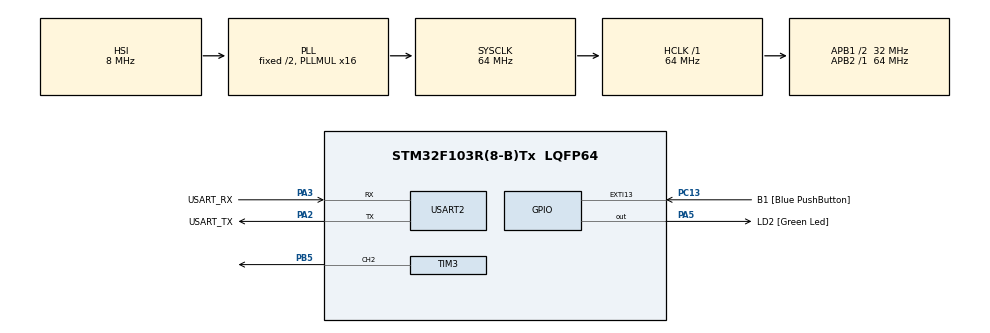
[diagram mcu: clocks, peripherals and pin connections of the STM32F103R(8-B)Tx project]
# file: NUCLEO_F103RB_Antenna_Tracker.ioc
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FREERTOS.Tasks01=blink01,24,128,StartBlink01,Default,NULL,Dynamic,NULL,NULL;PWM01,32,128,StartPWM01,Default,NULL,Dynamic,NULL,NULL
FREERTOS.configUSE_NEWLIB_REENTRANT=1
Mcu.Family=STM32F1
Mcu.Name=STM32F103R(8-B)Tx
Mcu.Package=LQFP64
NVIC.EXTI15_10_IRQn=true\:5\:0\:false\:false\:true\:true\:true\:true\:true
NVIC.PriorityGroup=NVIC_PRIORITYGROUP_4
NVIC.TIM4_IRQn=true\:15\:0\:false\:false\:true\:false\:false\:true\:true
NVIC.TimeBase=TIM4_IRQn
NVIC.TimeBaseIP=TIM4
PA13.GPIO_Label=TMS
PA13.Mode=Serial_Wire
PA13.Signal=SYS_JTMS-SWDIO
PA14.GPIO_Label=TCK
PA14.Mode=Serial_Wire
PA14.Signal=SYS_JTCK-SWCLK
PA2.GPIO_Label=USART_TX
PA2.GPIO_Mode=GPIO_MODE_AF_PP
PA2.GPIO_PuPd=GPIO_NOPULL
PA2.GPIO_Speed=GPIO_SPEED_FREQ_LOW
PA2.Mode=Asynchronous
PA2.Signal=USART2_TX
PA3.GPIO_Label=USART_RX
PA3.GPIO_Mode=GPIO_MODE_AF_PP
PA3.GPIO_PuPd=GPIO_NOPULL
PA3.GPIO_Speed=GPIO_SPEED_FREQ_LOW
PA3.Mode=Asynchronous
PA3.Signal=USART2_RX
PA5.GPIO_Label=LD2 [Green Led]
PA5.GPIO_ModeDefaultOutputPP=GPIO_MODE_OUTPUT_PP
PA5.GPIO_PuPd=GPIO_NOPULL
PA5.GPIO_Speed=GPIO_SPEED_FREQ_LOW
PA5.Signal=GPIO_Output
PB3.GPIO_Label=SWO
PB3.Signal=SYS_JTDO-TRACESWO
PB5.Signal=S_TIM3_CH2
PC13-TAMPER-RTC.GPIO_Label=B1 [Blue PushButton]
PC13-TAMPER-RTC.GPIO_PuPd=GPIO_NOPULL
PC13-TAMPER-RTC.Signal=GPXTI13
PC14-OSC32_IN.Mode=LSE-External-Oscillator
PC14-OSC32_IN.Signal=RCC_OSC32_IN
PC15-OSC32_OUT.Mode=LSE-External-Oscillator
PC15-OSC32_OUT.Signal=RCC_OSC32_OUT
PD0-OSC_IN.Mode=HSE-External-Clock-Source
PD0-OSC_IN.Signal=RCC_OSC_IN
PD1-OSC_OUT.Mode=HSE-External-Clock-Source
PD1-OSC_OUT.Signal=RCC_OSC_OUT
ProjectManager.HeapSize=0x200
ProjectManager.StackSize=0x400
ProjectManager.TargetToolchain=STM32CubeIDE
RCC.AHBFreq_Value=64000000
RCC.APB1CLKDivider=RCC_HCLK_DIV2
RCC.APB1Freq_Value=32000000
RCC.APB1TimFreq_Value=64000000
RCC.APB2Freq_Value=64000000
RCC.APB2TimFreq_Value=64000000
RCC.HCLKFreq_Value=64000000
RCC.PLLMUL=RCC_PLL_MUL16
RCC.RTCClockSelection=RCC_RTCCLKSOURCE_LSE
RCC.SYSCLKFreq_VALUE=64000000
RCC.SYSCLKSource=RCC_SYSCLKSOURCE_PLLCLK
RCC.USBFreq_Value=64000000
SH.S_TIM3_CH2.0=TIM3_CH2,PWM Generation2 CH2
TIM3.Channel-PWM\ Generation2\ CH2=TIM_CHANNEL_2
TIM3.Period=6400-1
TIM3.Prescaler=200-1
USART2.VirtualMode=VM_ASYNC
VP_FREERTOS_VS_CMSIS_V2.Mode=CMSIS_V2
VP_SYS_VS_tim4.Mode=TIM4
VP_TIM3_VS_ClockSourceINT.Mode=Internal
board=NUCLEO-F103RB

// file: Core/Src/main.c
/* USER CODE BEGIN Header */
/**
  ******************************************************************************
  * @file           : main.c
  * @brief          : Main program body
  ******************************************************************************
  * @attention
  *
  * Copyright (c) 2025 STMicroelectronics.
  * All rights reserved.
  *
  * This software is licensed under terms that can be found in the LICENSE file
  * in the root directory of this software component.
  * If no LICENSE file comes with this software, it is provided AS-IS.
  *
  ******************************************************************************
  */
/* USER CODE END Header */
#include "main.h"
#include "cmsis_os.h"

TIM_HandleTypeDef htim3;

UART_HandleTypeDef huart2;

/* Definitions for blink01 */
osThreadId_t blink01Handle;
const osThreadAttr_t blink01_attributes = {
  .name = "blink01",
  .stack_size = 128 * 4,
  .priority = (osPriority_t) osPriorityNormal,
};
/* Definitions for PWM01 */
osThreadId_t PWM01Handle;
const osThreadAttr_t PWM01_attributes = {
  .name = "PWM01",
  .stack_size = 128 * 4,
  .priority = (osPriority_t) osPriorityAboveNormal,
};

void SystemClock_Config(void);
static void MX_GPIO_Init(void);
static void MX_USART2_UART_Init(void);
static void MX_TIM3_Init(void);
void StartBlink01(void *argument);
void StartPWM01(void *argument);

/* USER CODE BEGIN 0 */
void Set_Servo_Angle (TIM_HandleTypeDef *htim, uint32_t channel, int angle)
{
	//map angle (0-180) to PW (160-800 counts)
	//160 for 0.5ms (0 degrees) 800 for 2.5ms (180 degrees)
	uint32_t pulse_length = 160 + (angle *(800 - 160)/180);

	__HAL_TIM_SET_COMPARE(htim, channel, pulse_length);
}

/* USER CODE END 0 */

int main(void)
{

  /* MCU Configuration--------------------------------------------------------*/

  /* Reset of all peripherals, Initializes the Flash interface and the Systick. */
  HAL_Init();

  /* Configure the system clock */
  SystemClock_Config();

  /* Initialize all configured peripherals */
  MX_GPIO_Init();
  MX_USART2_UART_Init();
  MX_TIM3_Init();
  /* USER CODE BEGIN 2 */
  HAL_TIM_PWM_Start(&htim3, TIM_CHANNEL_2);
  /* USER CODE END 2 */

  /* Init scheduler */
  osKernelInitialize();

  /* Create the thread(s) */
  /* creation of blink01 */
  blink01Handle = osThreadNew(StartBlink01, NULL, &blink01_attributes);

  /* creation of PWM01 */
  PWM01Handle = osThreadNew(StartPWM01, NULL, &PWM01_attributes);

  /* Start scheduler */
  osKernelStart();

  /* We should never get here as control is now taken by the scheduler */

  /* Infinite loop */
  while (1)
  {

  }
}

void SystemClock_Config(void)
{
  RCC_OscInitTypeDef RCC_OscInitStruct = {0};
  RCC_ClkInitTypeDef RCC_ClkInitStruct = {0};

  /** Initializes the RCC Oscillators according to the specified parameters
  * in the RCC_OscInitTypeDef structure.
  */
  RCC_OscInitStruct.OscillatorType = RCC_OSCILLATORTYPE_HSI;
  RCC_OscInitStruct.HSIState = RCC_HSI_ON;
  RCC_OscInitStruct.HSICalibrationValue = RCC_HSICALIBRATION_DEFAULT;
  RCC_OscInitStruct.PLL.PLLState = RCC_PLL_ON;
  RCC_OscInitStruct.PLL.PLLSource = RCC_PLLSOURCE_HSI_DIV2;
  RCC_OscInitStruct.PLL.PLLMUL = RCC_PLL_MUL16;
  if (HAL_RCC_OscConfig(&RCC_OscInitStruct) != HAL_OK)
  {
    Error_Handler();
  }

  /** Initializes the CPU, AHB and APB buses clocks
  */
  RCC_ClkInitStruct.ClockType = RCC_CLOCKTYPE_HCLK|RCC_CLOCKTYPE_SYSCLK
                              |RCC_CLOCKTYPE_PCLK1|RCC_CLOCKTYPE_PCLK2;
  RCC_ClkInitStruct.SYSCLKSource = RCC_SYSCLKSOURCE_PLLCLK;
  RCC_ClkInitStruct.AHBCLKDivider = RCC_SYSCLK_DIV1;
  RCC_ClkInitStruct.APB1CLKDivider = RCC_HCLK_DIV2;
  RCC_ClkInitStruct.APB2CLKDivider = RCC_HCLK_DIV1;

  if (HAL_RCC_ClockConfig(&RCC_ClkInitStruct, FLASH_LATENCY_2) != HAL_OK)
  {
    Error_Handler();
  }
}

static void MX_TIM3_Init(void)
{

  TIM_ClockConfigTypeDef sClockSourceConfig = {0};
  TIM_MasterConfigTypeDef sMasterConfig = {0};
  TIM_OC_InitTypeDef sConfigOC = {0};

  htim3.Instance = TIM3;
  htim3.Init.Prescaler = 200-1;
  htim3.Init.CounterMode = TIM_COUNTERMODE_UP;
  htim3.Init.Period = 6400-1;
  htim3.Init.ClockDivision = TIM_CLOCKDIVISION_DIV1;
  htim3.Init.AutoReloadPreload = TIM_AUTORELOAD_PRELOAD_DISABLE;
  if (HAL_TIM_Base_Init(&htim3) != HAL_OK)
  {
    Error_Handler();
  }
  sClockSourceConfig.ClockSource = TIM_CLOCKSOURCE_INTERNAL;
  if (HAL_TIM_ConfigClockSource(&htim3, &sClockSourceConfig) != HAL_OK)
  {
    Error_Handler();
  }
  if (HAL_TIM_PWM_Init(&htim3) != HAL_OK)
  {
    Error_Handler();
  }
  sMasterConfig.MasterOutputTrigger = TIM_TRGO_RESET;
  sMasterConfig.MasterSlaveMode = TIM_MASTERSLAVEMODE_DISABLE;
  if (HAL_TIMEx_MasterConfigSynchronization(&htim3, &sMasterConfig) != HAL_OK)
  {
    Error_Handler();
  }
  sConfigOC.OCMode = TIM_OCMODE_PWM1;
  sConfigOC.Pulse = 0;
  sConfigOC.OCPolarity = TIM_OCPOLARITY_HIGH;
  sConfigOC.OCFastMode = TIM_OCFAST_DISABLE;
  if (HAL_TIM_PWM_ConfigChannel(&htim3, &sConfigOC, TIM_CHANNEL_2) != HAL_OK)
  {
    Error_Handler();
  }
  HAL_TIM_MspPostInit(&htim3);

}

static void MX_USART2_UART_Init(void)
{

  huart2.Instance = USART2;
  huart2.Init.BaudRate = 115200;
  huart2.Init.WordLength = UART_WORDLENGTH_8B;
  huart2.Init.StopBits = UART_STOPBITS_1;
  huart2.Init.Parity = UART_PARITY_NONE;
  huart2.Init.Mode = UART_MODE_TX_RX;
  huart2.Init.HwFlowCtl = UART_HWCONTROL_NONE;
  huart2.Init.OverSampling = UART_OVERSAMPLING_16;
  if (HAL_UART_Init(&huart2) != HAL_OK)
  {
    Error_Handler();
  }

}

static void MX_GPIO_Init(void)
{
  GPIO_InitTypeDef GPIO_InitStruct = {0};

  /* GPIO Ports Clock Enable */
  __HAL_RCC_GPIOC_CLK_ENABLE();
  __HAL_RCC_GPIOD_CLK_ENABLE();
  __HAL_RCC_GPIOA_CLK_ENABLE();
  __HAL_RCC_GPIOB_CLK_ENABLE();

  /*Configure GPIO pin Output Level */
  HAL_GPIO_WritePin(LD2_GPIO_Port, LD2_Pin, GPIO_PIN_RESET);

  /*Configure GPIO pin : B1_Pin */
  GPIO_InitStruct.Pin = B1_Pin;
  GPIO_InitStruct.Mode = GPIO_MODE_IT_RISING;
  GPIO_InitStruct.Pull = GPIO_NOPULL;
  HAL_GPIO_Init(B1_GPIO_Port, &GPIO_InitStruct);

  /*Configure GPIO pin : LD2_Pin */
  GPIO_InitStruct.Pin = LD2_Pin;
  GPIO_InitStruct.Mode = GPIO_MODE_OUTPUT_PP;
  GPIO_InitStruct.Pull = GPIO_NOPULL;
  GPIO_InitStruct.Speed = GPIO_SPEED_FREQ_LOW;
  HAL_GPIO_Init(LD2_GPIO_Port, &GPIO_InitStruct);

  /* EXTI interrupt init*/
  HAL_NVIC_SetPriority(EXTI15_10_IRQn, 5, 0);
  HAL_NVIC_EnableIRQ(EXTI15_10_IRQn);

}

void StartBlink01(void *argument)
{
  /* USER CODE BEGIN 5 */
  /* Infinite loop */
  for(;;)
  {
	HAL_GPIO_TogglePin(GPIOA, GPIO_PIN_5);
    osDelay(500);
  }
  osThreadTerminate(NULL);
  /* USER CODE END 5 */
}

void StartPWM01(void *argument)
{
  /* USER CODE BEGIN StartPWM01 */
  /* Infinite loop */
  for(;;)
  {

	  //------------------------------TEST SWEEP-------------------------

	  for (int angle = 0; angle <= 180; angle+= 30) {
		  Set_Servo_Angle(&htim3, TIM_CHANNEL_2, angle);
	  		osDelay(100);
	  }
	  for (int angle = 180; angle > 0; angle-= 30) {
		  Set_Servo_Angle(&htim3, TIM_CHANNEL_2, angle);
	  		osDelay(100);
	  }

	  //Set_Servo_Angle(&htim3, TIM_CHANNEL_2, 180);
	  //------------------------------TEST SWEEP END--------------------

  }
  osThreadTerminate(NULL);
  /* USER CODE END StartPWM01 */
}

void HAL_TIM_PeriodElapsedCallback(TIM_HandleTypeDef *htim)
{
  if (htim->Instance == TIM4)
  {
    HAL_IncTick();
  }
}

void Error_Handler(void)
{
  __disable_irq();
  while (1)
  {
  }
}
